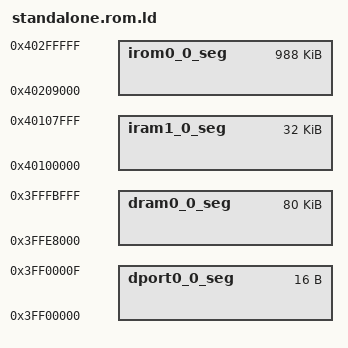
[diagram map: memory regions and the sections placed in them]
/* linker script for espressif bootloader */

MEMORY
{
  dport0_0_seg :                        org = 0x3FF00000, len = 0x10
  dram0_0_seg :                         org = 0x3FFE8000, len = 0x14000
  iram1_0_seg :                         org = 0x40100000, len = 0x8000
  irom0_0_seg :                         org = 0x40209000, len = (1M - 0x9000)
}

INCLUDE "common.ld"
